# STM32MP157 register map
File version: 1.7
CPU: CM4 r0p1, little endian, no MPU, FPU, 4 interrupt priority bits
Registers are 32-bit, read-write, reset 0x0 unless marked. A register's access mark holds for its fields unless they carry their own. Offsets are from the block's base; [hi:lo] are bit positions; {n}, {i} and the like mark numbered series.

## GICH
Base 0xA0024000
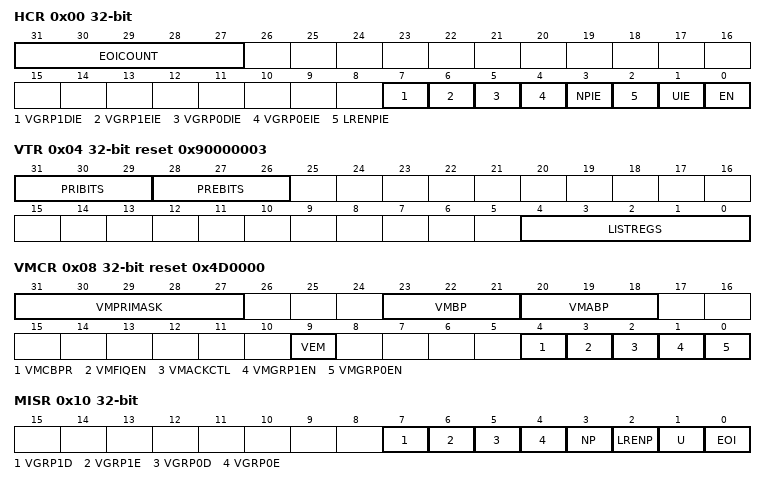
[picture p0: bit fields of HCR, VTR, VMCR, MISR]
0x00 HCR — GICH hypervisor control register
  [31:27] EOICOUNT, [7] VGRP1DIE, [6] VGRP1EIE, [5] VGRP0DIE, [4] VGRP0EIE, [3] NPIE, [2] LRENPIE, [1] UIE, [0] EN
0x04 VTR ro reset 0x90000003 — GICH VGIC type register
  [31:29] PRIBITS, [28:26] PREBITS, [4:0] LISTREGS
0x08 VMCR reset 0x4D0000 — GICH virtual machine control register
  [31:27] VMPRIMASK, [23:21] VMBP, [20:18] VMABP, [9] VEM, [4] VMCBPR, [3] VMFIQEN, [2] VMACKCTL, [1] VMGRP1EN, [0] VMGRP0EN
0x10 MISR ro — GICH maintenance interrupt status register
  [7] VGRP1D, [6] VGRP1E, [5] VGRP0D, [4] VGRP0E, [3] NP, [2] LRENP, [1] U, [0] EOI
0x20 EISR0 ro — GICH end of interrupt status register
0x30 ELSR0 ro reset 0xF — GICH empty list status register
0xF0 APR0 — GICH active priority register
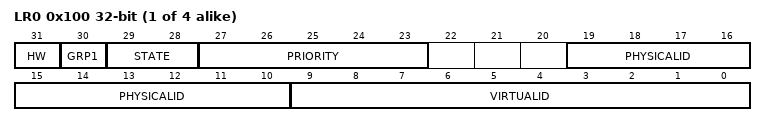
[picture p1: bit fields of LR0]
{0x100+4i} LR{i} (i=0..3) — GICH list register {i}
  [31] HW, [30] GRP1, [29:28] STATE, [27:23] PRIORITY, [19:10] PHYSICALID, [9:0] VIRTUALID

## GICV
Base 0xA0026000
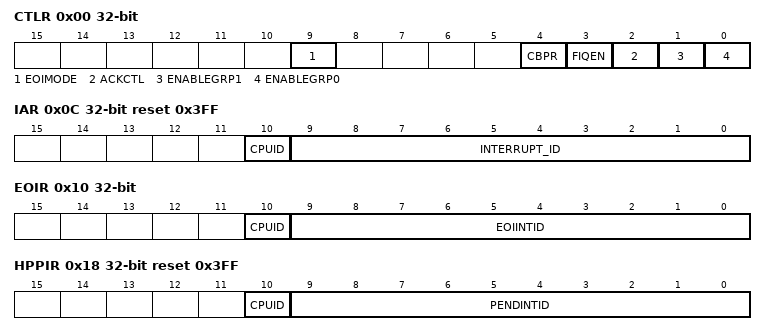
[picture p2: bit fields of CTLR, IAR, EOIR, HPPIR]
0x00 CTLR — GICV virtual machine control register
  [9] EOIMODE, [4] CBPR, [3] FIQEN, [2] ACKCTL, [1] ENABLEGRP1, [0] ENABLEGRP0
0x04 PMR — GICV VM priority mask register
  [7:3] PRIORITY
0x08 BPR reset 0x2 — GICV VM binary point register
  [2:0] BINARY_POINT
0x0C IAR ro reset 0x3FF — GICV VM interrupt acknowledge register
  [10] CPUID, [9:0] INTERRUPT_ID
0x10 EOIR wo — GICV VM end of interrupt register
  [10] CPUID, [9:0] EOIINTID
0x14 RPR ro reset 0xFF — GICV VM running priority register
  [7:3] PRIORITY
0x18 HPPIR ro reset 0x3FF — GICV VM highest priority pending interrupt register
  [10] CPUID, [9:0] PENDINTID
0x1C ABPR reset 0x3 — GICV VM aliased binary point register
  [2:0] BINARY_POINT
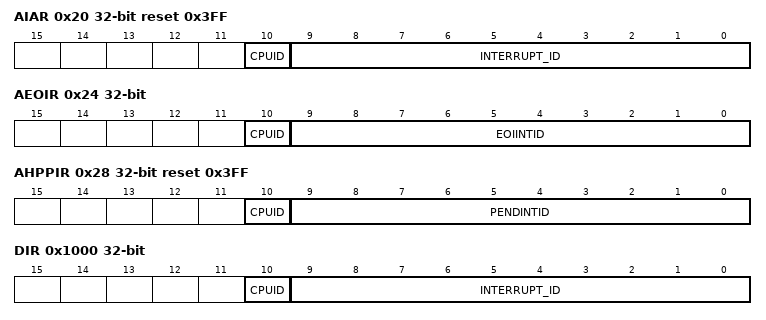
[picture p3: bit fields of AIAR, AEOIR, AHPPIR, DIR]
0x20 AIAR ro reset 0x3FF — GICV VM aliased interrupt register
  [10] CPUID, [9:0] INTERRUPT_ID
0x24 AEOIR wo — GICV VM aliased end of interrupt register
  [10] CPUID, [9:0] EOIINTID
0x28 AHPPIR ro reset 0x3FF — GICV VM aliased highest priority pending interrupt register
  [10] CPUID, [9:0] PENDINTID
0xD0 APR0 — The GICV_APR0 is an alias of GICH_APR.
0xFC IIDR ro reset 0x102143B — The GICV_IIDR is an alias of GICC_IIDR.
0x1000 DIR wo — GICV VM deactivate interrupt register
  [10] CPUID, [9:0] INTERRUPT_ID

## GPIOZ
Base 0x54004000
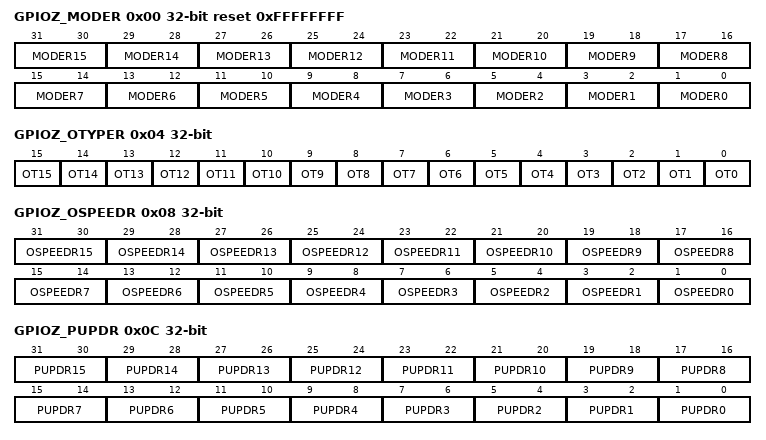
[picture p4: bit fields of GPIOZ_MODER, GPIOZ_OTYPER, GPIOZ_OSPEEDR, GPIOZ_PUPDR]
0x00 GPIOZ_MODER reset 0xFFFFFFFF — GPIO port mode register
  [2n+1:2n] MODER{n} (n=0..15)
0x04 GPIOZ_OTYPER — GPIO port output type register
  [n] OT{n} (n=0..15)
0x08 GPIOZ_OSPEEDR — GPIO port output speed register
  [2n+1:2n] OSPEEDR{n} (n=0..15)
0x0C GPIOZ_PUPDR — GPIO port pull-up/pull-down register
  [2n+1:2n] PUPDR{n} (n=0..15)
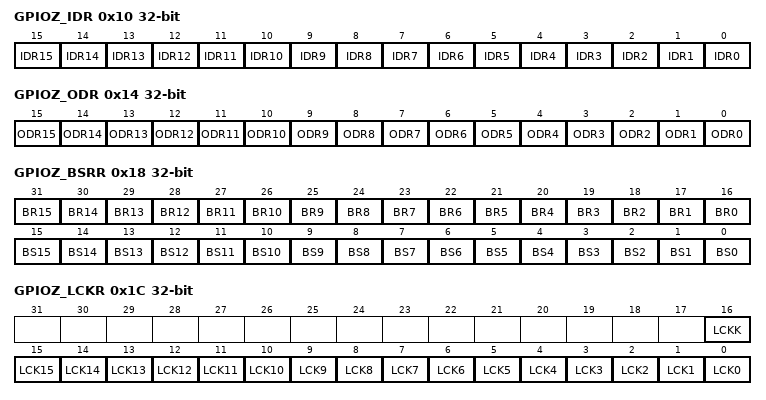
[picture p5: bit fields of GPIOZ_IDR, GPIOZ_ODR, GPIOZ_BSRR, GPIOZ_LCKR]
0x10 GPIOZ_IDR ro — GPIO port input data register
  [n] IDR{n} (n=0..15)
0x14 GPIOZ_ODR — GPIO port output data register
  [n] ODR{n} (n=0..15)
0x18 GPIOZ_BSRR wo — GPIO port bit set/reset register
  [n+16] BR{n} (n=0..15), [n] BS{n} (n=0..15)
0x1C GPIOZ_LCKR — This register is used to lock the configuration of the port bits when a correct write sequence is applied to bit 16 (LCKK). The value of bits [15:0] is used to lock the configuration of the GPIO. During the write sequence, the value of LCKR[15:0] must not change. When the LOCK sequence has been applied on a port bit, the value of this port bit can no longer be modified until the next MCU reset or peripheral reset. A specific write sequence is used to write to the GPIOx_LCKR register. Only word access (32-bit long) is allowed during this locking sequence. Each lock bit freezes a specific configuration register (control and alternate function registers).
  [16] LCKK, [n] LCK{n} (n=0..15)
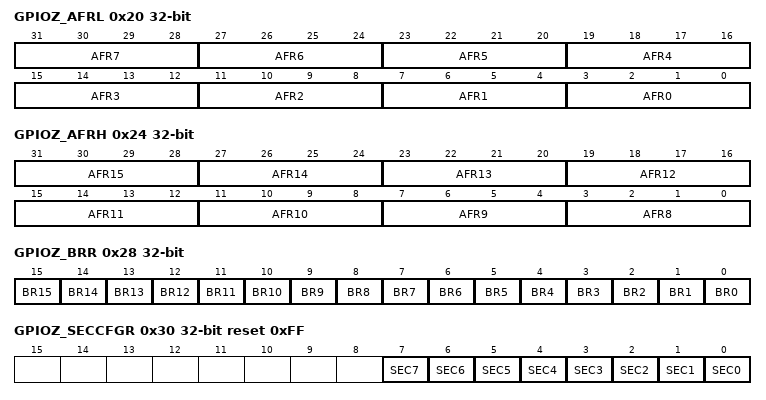
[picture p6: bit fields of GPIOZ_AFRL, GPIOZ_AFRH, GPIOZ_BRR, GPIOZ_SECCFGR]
0x20 GPIOZ_AFRL — GPIO alternate function low register
  [4n+3:4n] AFR{n} (n=0..7)
0x24 GPIOZ_AFRH — GPIO alternate function high register
  [4n-29:4n-32] AFR{n} (n=8..15)
0x28 GPIOZ_BRR wo — GPIO port bit reset register
  [n] BR{n} (n=0..15)
0x30 GPIOZ_SECCFGR wo reset 0xFF — This register provides write access security and can be written only by a secure access. It is used to configure a selected I/O as secure. A non-secure write access to this register is discarded.
  [n] SEC{n} (n=0..7)
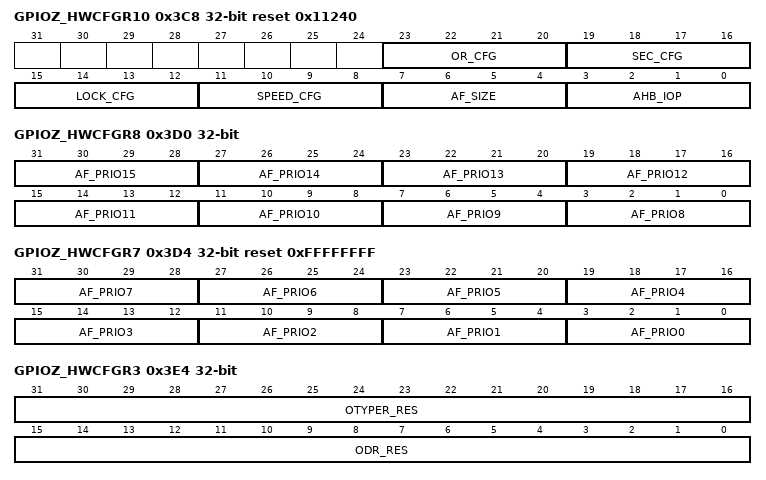
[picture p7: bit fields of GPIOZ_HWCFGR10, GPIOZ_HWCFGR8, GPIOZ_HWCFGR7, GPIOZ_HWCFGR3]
0x3C8 GPIOZ_HWCFGR10 ro reset 0x11240 — For GPIOA, B, C, D, E, F, G, H, I, J and GPIOK: For GPIOZ:
  [23:20] OR_CFG, [19:16] SEC_CFG, [15:12] LOCK_CFG, [11:8] SPEED_CFG, [7:4] AF_SIZE, [3:0] AHB_IOP
0x3CC GPIOZ_HWCFGR9 ro reset 0xFF — For GPIOA, B, C, D, E, F, G, H, I, and GPIOJ: For GPIOK and GPIOZ:
  [15:0] EN_IO
0x3D0 GPIOZ_HWCFGR8 ro — For GPIOA, B, C, D, E, F, G, H, I, and GPIOJ: For GPIOK and GPIOZ:
  [4n-29:4n-32] AF_PRIO{n} (n=8..15)
0x3D4 GPIOZ_HWCFGR7 ro reset 0xFFFFFFFF — GPIO hardware configuration register 7
  [4n+3:4n] AF_PRIO{n} (n=0..7)
0x3D8 GPIOZ_HWCFGR6 ro reset 0xFFFFFFFF — GPIO hardware configuration register 6
  [31:0] MODER_RES
0x3DC GPIOZ_HWCFGR5 ro — GPIO hardware configuration register 5
  [31:0] PUPDR_RES
0x3E0 GPIOZ_HWCFGR4 ro — GPIO hardware configuration register 4
  [31:0] OSPEED_RES
0x3E4 GPIOZ_HWCFGR3 ro — GPIO hardware configuration register 3
  [31:16] OTYPER_RES, [15:0] ODR_RES
0x3E8 GPIOZ_HWCFGR2 ro — GPIO hardware configuration register 2
  [31:0] AFRL_RES
0x3EC GPIOZ_HWCFGR1 ro — GPIO hardware configuration register 1
  [31:0] AFRH_RES
0x3F0 GPIOZ_HWCFGR0 ro — GPIO hardware configuration register 0
  [15:0] OR_RES
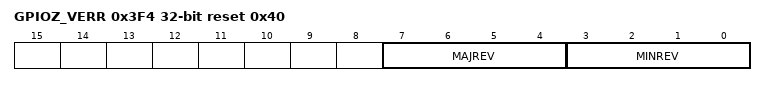
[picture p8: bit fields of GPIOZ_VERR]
0x3F4 GPIOZ_VERR ro reset 0x40 — GPIO version register
  [7:4] MAJREV, [3:0] MINREV
0x3F8 GPIOZ_IPIDR ro reset 0xF0002 — GPIO identification register
0x3FC GPIOZ_SIDR ro reset 0xA3C5DD01 — GPIO size identification register
